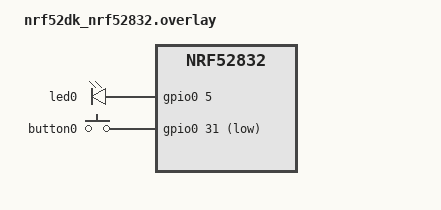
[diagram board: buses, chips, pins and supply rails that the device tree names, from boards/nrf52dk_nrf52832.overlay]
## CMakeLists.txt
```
# SPDX-License-Identifier: Apache-2.0

cmake_minimum_required(VERSION 3.20.0)
find_package(Zephyr REQUIRED HINTS $ENV{ZEPHYR_BASE})
project(blinky_1)

target_sources(app PRIVATE
    src/main.c
    src/uart_switch.c
    src/led.c
    src/gps.c
    src/modem.c
    src/ble.c
    src/state_machine.c
)
```

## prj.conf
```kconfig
CONFIG_GPIO=y

# nrfx UARTE0 owned directly (single UART, runtime pin-swap)
CONFIG_NRFX_UARTE0=y

# RTT for debug (UART0 hardware is used for GPS/modem)
CONFIG_USE_SEGGER_RTT=y
CONFIG_RTT_CONSOLE=y
CONFIG_UART_CONSOLE=n

# BLE + Nordic UART Service (NUS) for phone connection
CONFIG_BT=y
CONFIG_BT_PERIPHERAL=y
CONFIG_BT_NUS=y
CONFIG_BT_DEVICE_NAME="AKT-01"
CONFIG_BT_MAX_CONN=1

# FPU for double-precision GPS coordinates
CONFIG_FPU=y

# GPIOTE for interrupt-driven button
CONFIG_NRFX_GPIOTE=y

# Stack sizes
CONFIG_MAIN_STACK_SIZE=2048
CONFIG_SYSTEM_WORKQUEUE_STACK_SIZE=1024
```

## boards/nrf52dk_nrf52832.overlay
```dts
/ {
	chosen {
		zephyr,console = &rtt0;
		zephyr,shell-uart = &rtt0;
	};
};

&led0 {
	gpios = <&gpio0 5 GPIO_ACTIVE_HIGH>;
};

&button0 {
	gpios = <&gpio0 31 (GPIO_PULL_UP | GPIO_ACTIVE_LOW)>;
};

&uart0 {
	status = "disabled";
};
```

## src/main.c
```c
#include <zephyr/kernel.h>
#include <zephyr/sys/printk.h>
#include "uart_switch.h"
#include "led.h"
#include "gps.h"
#include "modem.h"
#include "ble.h"
#include "state_machine.h"

int main(void)
{
    printk("AKT-01 tracker boot\n");

    uart_switch_init();
    led_init();
    gps_init();
    ble_init();
    modem_init();
    state_machine_init();

    printk("Boot complete\n");

    state_machine_run();

    return 0;
}
```

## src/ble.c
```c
#include "ble.h"
#include <zephyr/kernel.h>
#include <zephyr/sys/util.h>
#include <zephyr/bluetooth/bluetooth.h>
#include <zephyr/bluetooth/conn.h>
#include <bluetooth/services/nus.h>
#include <string.h>
#include <zephyr/sys/printk.h>

static const struct bt_data ad[] = {
    BT_DATA_BYTES(BT_DATA_FLAGS, (BT_LE_AD_GENERAL | BT_LE_AD_NO_BREDR)),
    BT_DATA_BYTES(BT_DATA_UUID128_ALL, BT_UUID_NUS_VAL),
};

static const struct bt_data sd[] = {
    BT_DATA(BT_DATA_NAME_COMPLETE,
            CONFIG_BT_DEVICE_NAME,
            sizeof(CONFIG_BT_DEVICE_NAME) - 1),
};

static struct bt_conn *m_conn;

static void on_connected(struct bt_conn *conn, uint8_t err)
{
    if (err) {
        printk("BLE: connect failed (err %u)\n", err);
        return;
    }
    printk("BLE: phone connected\n");
    m_conn = bt_conn_ref(conn);
}

static void on_disconnected(struct bt_conn *conn, uint8_t reason)
{
    printk("BLE: phone disconnected (reason %u)\n", reason);
    if (m_conn) {
        bt_conn_unref(m_conn);
        m_conn = NULL;
    }

    bt_le_adv_start(BT_LE_ADV_CONN_FAST_1, ad, ARRAY_SIZE(ad), sd, ARRAY_SIZE(sd));
}

BT_CONN_CB_DEFINE(conn_callbacks) = {
    .connected    = on_connected,
    .disconnected = on_disconnected,
};

static void nus_received(struct bt_conn *conn, const uint8_t *data, uint16_t len)
{
    printk("BLE: rx %u bytes: %.*s\n", len, len, (const char *)data);
}

static struct bt_nus_cb nus_cb = {
    .received = nus_received,
};

void ble_init(void)
{
    int err = bt_enable(NULL);
    if (err) {
        printk("BLE: init failed (%d)\n", err);
        return;
    }

    err = bt_nus_init(&nus_cb);
    if (err) {
        printk("BLE: NUS init failed (%d)\n", err);
        return;
    }

    printk("BLE: initialized\n");

}

void ble_start(void)
{
    int err = bt_le_adv_start(BT_LE_ADV_CONN_FAST_1,
                               ad, ARRAY_SIZE(ad),
                               sd, ARRAY_SIZE(sd));
    if (err && err != -EALREADY) {
        printk("BLE: adv start failed (%d)\n", err);
    } else {
        printk("BLE: advertising as \"%s\"\n", CONFIG_BT_DEVICE_NAME);
    }
}

void ble_stop(void)
{
    if (m_conn) {
        bt_conn_disconnect(m_conn, BT_HCI_ERR_REMOTE_USER_TERM_CONN);
    }
    int err = bt_le_adv_stop();
    if (err) {
        printk("BLE: adv stop failed (%d)\n", err);
    }
    printk("BLE: stopped\n");
}

void ble_send_status(const char *text)
{
    if (m_conn) {
        bt_nus_send(m_conn, (const uint8_t *)text, strlen(text));
    }
}
```

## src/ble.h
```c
#ifndef BLE_H
#define BLE_H

void ble_init(void);

void ble_start(void);

void ble_stop(void);

void ble_send_status(const char *text);

#endif 
```

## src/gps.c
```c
#include "gps.h"
#include "uart_switch.h"
#include <zephyr/kernel.h>
#include <stdlib.h>
#include <string.h>
#include <zephyr/sys/printk.h>

#define PMTK_STANDBY  "$PMTK161,0*28\r\n"
#define PMTK_WAKE     "$PMTK010,001*2E\r\n"

#define GPS_LINE_MAX  96u

static gps_fix_t  m_fix;
static char       m_line[GPS_LINE_MAX];
static uint8_t    m_line_len;

static double nmea_coord_to_decimal(const char *field, char hem)
{
    if (field[0] == '\0') {
        return 0.0;
    }
    int degree_digits = (hem == 'N' || hem == 'S') ? 2 : 3;

    char deg_str[4] = {0};
    memcpy(deg_str, field, degree_digits);

    double degrees = atof(deg_str);
    double minutes  = atof(field + degree_digits);
    double decimal  = degrees + (minutes / 60.0);

    if (hem == 'S' || hem == 'W') {
        decimal = -decimal;
    }
    return decimal;
}

static int split_fields(char *line, char *fields[], int max_fields)
{
    int count = 0;
    char *tok = line;

    while (count < max_fields) {
        fields[count++] = tok;
        char *comma = strchr(tok, ',');
        if (!comma) {
            break;
        }
        *comma = '\0';
        tok    = comma + 1;
    }
    return count;
}

static bool parse_gga(char *sentence)
{
    char *fields[15];
    int n = split_fields(sentence, fields, 15);

    if (n < 8) {
        return false;
    }

    int quality = atoi(fields[6]);
    if (quality == 0) {
        m_fix.valid = false;
        return false;
    }

    m_fix.latitude   = nmea_coord_to_decimal(fields[2], fields[3][0]);
    m_fix.longitude  = nmea_coord_to_decimal(fields[4], fields[5][0]);
    m_fix.satellites = (uint8_t)atoi(fields[7]);
    m_fix.valid      = true;
    return true;
}

static bool process_line(char *line)
{
    if (line[0] != '$') {
        return false;
    }

    char *star = strchr(line, '*');
    if (star) {
        *star = '\0';
    }

    if (strncmp(line + 1, "GPGGA", 5) == 0 ||
        strncmp(line + 1, "GNGGA", 5) == 0) {
        return parse_gga(line);
    }
    return false;
}

bool gps_feed_byte(uint8_t byte)
{
    if (byte == '\r') {
        return false;
    }
    if (byte == '\n') {
        bool got_fix = false;
        if (m_line_len > 0) {
            m_line[m_line_len] = '\0';
            got_fix = process_line(m_line);
        }
        m_line_len = 0;
        return got_fix;
    }
    if (m_line_len < GPS_LINE_MAX - 1u) {
        m_line[m_line_len++] = byte;
    }
    return false;
}

gps_fix_t gps_get_fix(void)
{
    return m_fix;
}

void gps_init(void)
{
    memset(&m_fix, 0, sizeof(m_fix));
    m_line_len = 0;
}

void gps_enter_standby(void)
{
    uart_switch_to_gps();
    uart_write_str(PMTK_STANDBY);
    k_sleep(K_MSEC(200));
}

bool gps_acquire_fix(gps_fix_t *fix, int timeout_ms)
{
    uart_switch_to_gps();
    uart_flush_rx();

    uart_write_str(PMTK_WAKE);

    int64_t deadline = k_uptime_get() + timeout_ms;
    uint8_t byte;

    while (k_uptime_get() < deadline) {
        if (!uart_read_byte(&byte, K_MSEC(200))) {
            continue;
        }
        if (gps_feed_byte(byte) && m_fix.valid) {
            *fix = m_fix;
            printk("GPS fix: lat=%d.%06d lon=%d.%06d sats=%u\n",
                   (int)m_fix.latitude,
                   (int)((m_fix.latitude < 0 ? -m_fix.latitude : m_fix.latitude) * 1e6) % 1000000,
                   (int)m_fix.longitude,
                   (int)((m_fix.longitude < 0 ? -m_fix.longitude : m_fix.longitude) * 1e6) % 1000000,
                   m_fix.satellites);
            return true;
        }
    }

    printk("GPS: fix timeout\n");
    return false;
}
```

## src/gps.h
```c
#ifndef GPS_H
#define GPS_H

#include <stdbool.h>
#include <stdint.h>

typedef struct {
    double  latitude;
    double  longitude;
    uint8_t satellites;
    bool    valid;
} gps_fix_t;

void gps_init(void);

bool gps_acquire_fix(gps_fix_t *fix, int timeout_ms);

void gps_enter_standby(void);

bool gps_feed_byte(uint8_t byte);

gps_fix_t gps_get_fix(void);

#endif
```

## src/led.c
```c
#include "led.h"
#include <zephyr/kernel.h>
#include <zephyr/drivers/gpio.h>

#define LED_NODE DT_ALIAS(led0)
static const struct gpio_dt_spec m_led = GPIO_DT_SPEC_GET(LED_NODE, gpios);

void led_init(void)
{
    gpio_pin_configure_dt(&m_led, GPIO_OUTPUT_INACTIVE);
}

void led_tx_on(void)
{
    gpio_pin_set_dt(&m_led, 1);
}

void led_tx_off(void)
{
    gpio_pin_set_dt(&m_led, 0);
}

void led_blink_fail(void)
{
    for (int i = 0; i < 3; i++) {
        gpio_pin_set_dt(&m_led, 1);
        k_sleep(K_MSEC(80));
        gpio_pin_set_dt(&m_led, 0);
        k_sleep(K_MSEC(120));
    }
}
```

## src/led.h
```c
#ifndef LED_H
#define LED_H

void led_init(void);

void led_tx_on(void);
void led_tx_off(void);

void led_blink_fail(void);

#endif 
```

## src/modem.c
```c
#include "modem.h"
#include "uart_switch.h"
#include "led.h"
#include <zephyr/kernel.h>
#include <string.h>
#include <stdio.h>
#include <stdlib.h>
#include <zephyr/sys/printk.h>

#define AT_LINE_MAX   256u
#define AT_TIMEOUT_MS 10000

static char m_line[AT_LINE_MAX];

static int read_line(int timeout_ms)
{
    int64_t deadline = k_uptime_get() + timeout_ms;
    uint8_t byte;
    int     len = 0;

    while (k_uptime_get() < deadline) {
        if (!uart_read_byte(&byte, K_MSEC(100))) {
            continue;
        }
        if (byte == '\r') {
            continue;
        }
        if (byte == '\n') {
            m_line[len] = '\0';
            return len;
        }
        if (len < (int)(AT_LINE_MAX - 1)) {
            m_line[len++] = (char)byte;
        }
    }
    m_line[len] = '\0';
    return -1;
}

static bool at_send(const char *cmd, const char *expect, int timeout_ms)
{
    printk("AT >> %s\n", cmd);
    uart_write_str(cmd);
    uart_write_str("\r\n");

    int64_t deadline = k_uptime_get() + timeout_ms;
    while (k_uptime_get() < deadline) {
        int remaining = (int)(deadline - k_uptime_get());
        if (remaining <= 0) {
            break;
        }
        int n = read_line(remaining < 500 ? remaining : 500);
        if (n < 0) {
            break;
        }
        if (n == 0) {
            continue; 
        }
        printk("AT << %s\n", m_line);
        if (strstr(m_line, expect)) {
            return true;
        }
        if (strstr(m_line, "ERROR")) {
            return false;
        }
    }
    printk("AT timeout waiting for '%s'\n", expect);
    return false;
}

void modem_init(void)
{
    uart_switch_to_modem();
    uart_flush_rx();

    k_sleep(K_MSEC(2000));

    at_send("AT",          "OK",  AT_TIMEOUT_MS);
    at_send("ATE0",        "OK",  AT_TIMEOUT_MS);
    at_send("AT+CMEE=2",   "OK",  AT_TIMEOUT_MS);

    char cmd[128];
    snprintf(cmd, sizeof(cmd), "AT+CGDCONT=1,\"IP\",\"%s\"", MODEM_APN);
    at_send(cmd, "OK", AT_TIMEOUT_MS);

    printk("Modem init done\n");
}

void modem_sleep(void)
{
    uart_switch_to_modem();
    at_send("AT+CSCLK=1", "OK", AT_TIMEOUT_MS);
}

void modem_wake(void)
{
    uart_switch_to_modem();
    uart_write_str("AT\r\n");
    k_sleep(K_MSEC(300));
    at_send("AT+CSCLK=0", "OK", AT_TIMEOUT_MS);
}

bool modem_send_location(double lat, double lon)
{
    uart_switch_to_modem();
    uart_flush_rx();

    if (!at_send("AT+CREG?", "+CREG:", 15000)) {
        printk("Modem: not registered\n");
        return false;
    }
    if (!strstr(m_line, ",1") && !strstr(m_line, ",5")) {
        printk("Modem: registration status not OK: %s\n", m_line);
        return false;
    }

    at_send("AT+CGACT=1,1", "OK", 30000);

    int lat_sign = (lat < 0.0) ? -1 : 1;
    double lat_a = (lat < 0.0) ? -lat : lat;
    int lon_sign = (lon < 0.0) ? -1 : 1;
    double lon_a = (lon < 0.0) ? -lon : lon;

    int lat_deg  = (int)lat_a;
    int lat_frac = (int)((lat_a - lat_deg) * 1000000.0 + 0.5);
    int lon_deg  = (int)lon_a;
    int lon_frac = (int)((lon_a - lon_deg) * 1000000.0 + 0.5);

    char url[512];
    snprintf(url, sizeof(url),
             "AT+HTTPPARA=\"URL\",\"%s?lat=%s%d.%06d&lon=%s%d.%06d\"",
             TRACKER_ENDPOINT,
             (lat_sign < 0) ? "-" : "", lat_deg, lat_frac,
             (lon_sign < 0) ? "-" : "", lon_deg, lon_frac);

    if (!at_send("AT+HTTPINIT", "OK", 5000)) {
        return false;
    }
    if (!at_send("AT+HTTPPARA=\"CID\",1", "OK", 5000)) {
        at_send("AT+HTTPTERM", "OK", 5000);
        return false;
    }
    if (!at_send(url, "OK", 5000)) {
        at_send("AT+HTTPTERM", "OK", 5000);
        return false;
    }

    led_tx_on();

    bool ok = false;
    if (at_send("AT+HTTPACTION=0", "+HTTPACTION:", 30000)) {
        char *p = strstr(m_line, ",");
        if (p) {
            int status_code = atoi(p + 1);
            printk("HTTP status: %d\n", status_code);
            ok = (status_code == 200);
        }
    }

    led_tx_off();

    at_send("AT+HTTPTERM", "OK", 5000);

    return ok;
}
```

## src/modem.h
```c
#ifndef MODEM_H
#define MODEM_H

#include <stdbool.h>

#define TRACKER_ENDPOINT  "http://YOUR_APPS_SCRIPT_URL_HERE"

/*
 * APN for your SIM.  Beeline KZ example: "internet.beeline.kz"
 */
#define MODEM_APN  "internet"

void modem_init(void);

bool modem_send_location(double lat, double lon);

void modem_sleep(void);

void modem_wake(void);

#endif
```

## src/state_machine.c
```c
#include "state_machine.h"
#include "gps.h"
#include "modem.h"
#include "ble.h"
#include "led.h"
#include <zephyr/kernel.h>
#include <zephyr/drivers/gpio.h>
#include <zephyr/sys/printk.h>

/* ── State ───────────────────────────────────────────────────────────── */
typedef enum { STATE_SLEEP, STATE_AWAKE } device_state_t;
static volatile device_state_t m_state = STATE_SLEEP;

/* ── Button ──────────────────────────────────────────────────────────── */
#define BUTTON_NODE DT_ALIAS(sw0)
static const struct gpio_dt_spec m_btn = GPIO_DT_SPEC_GET(BUTTON_NODE, gpios);
static struct gpio_callback      m_btn_cb;

static K_SEM_DEFINE(m_btn_sem, 0, 1);

static void button_isr(const struct device *dev, struct gpio_callback *cb,
                        uint32_t pins)
{
    ARG_UNUSED(dev);
    ARG_UNUSED(cb);
    ARG_UNUSED(pins);
    k_sem_give(&m_btn_sem);
}

/* ── Cycle timer + semaphore ─────────────────────────────────────────── */
static K_SEM_DEFINE(m_cycle_sem, 0, 1);

static void cycle_timer_cb(struct k_timer *t)
{
    ARG_UNUSED(t);
    k_sem_give(&m_cycle_sem);
}

K_TIMER_DEFINE(m_cycle_timer, cycle_timer_cb, NULL);

/* ── Cycle thread ────────────────────────────────────────────────────── */
#define CYCLE_THREAD_STACK  4096
#define CYCLE_THREAD_PRIO   5

static void cycle_thread_fn(void *a, void *b, void *c)
{
    ARG_UNUSED(a); ARG_UNUSED(b); ARG_UNUSED(c);

    while (1) {
        k_sem_take(&m_cycle_sem, K_FOREVER);

        if (m_state != STATE_AWAKE) {
            continue;
        }

        printk("Cycle: starting fix→upload\n");

        /* ── GPS ─────────────────────────────────────────────────────── */
        gps_fix_t fix;
        bool got_fix = gps_acquire_fix(&fix, GPS_FIX_TIMEOUT_MS);

        if (!got_fix) {
            printk("Cycle: no GPS fix — skipping upload\n");
            led_blink_fail();
            continue;
        }

        /* ── Upload ──────────────────────────────────────────────────── */
        bool uploaded = modem_send_location(fix.latitude, fix.longitude);

        if (!uploaded) {
            printk("Cycle: upload failed\n");
            led_blink_fail();
        } else {
            printk("Cycle: upload OK\n");

            char buf[64];
            int lat_deg  = (int)(fix.latitude < 0 ? -fix.latitude : fix.latitude);
            int lat_frac = (int)((fix.latitude < 0 ? -fix.latitude : fix.latitude) * 1e6) % 1000000;
            int lon_deg  = (int)(fix.longitude < 0 ? -fix.longitude : fix.longitude);
            int lon_frac = (int)((fix.longitude < 0 ? -fix.longitude : fix.longitude) * 1e6) % 1000000;

            snprintf(buf, sizeof(buf), "%s%d.%06d,%s%d.%06d",
                     fix.latitude  < 0 ? "-" : "", lat_deg, lat_frac,
                     fix.longitude < 0 ? "-" : "", lon_deg, lon_frac);
            ble_send_status(buf);
        }
    }
}

K_THREAD_DEFINE(cycle_tid,
                CYCLE_THREAD_STACK,
                cycle_thread_fn,
                NULL, NULL, NULL,
                CYCLE_THREAD_PRIO, 0, 0);

/* ── State transitions ───────────────────────────────────────────────── */
static void enter_awake(void)
{
    printk("-> AWAKE\n");
    m_state = STATE_AWAKE;
    ble_start();
    k_sem_give(&m_cycle_sem);
    k_timer_start(&m_cycle_timer,
                  K_SECONDS(CYCLE_INTERVAL_S),
                  K_SECONDS(CYCLE_INTERVAL_S));
}

static void enter_sleep(void)
{
    printk("-> SLEEP\n");
    m_state = STATE_SLEEP;
    k_timer_stop(&m_cycle_timer);
    ble_stop();
    gps_enter_standby();
    modem_sleep();
}

/* ── Public API ──────────────────────────────────────────────────────── */

void state_machine_init(void)
{
    gpio_pin_configure_dt(&m_btn, GPIO_INPUT);
    gpio_pin_interrupt_configure_dt(&m_btn, GPIO_INT_EDGE_TO_ACTIVE);
    gpio_init_callback(&m_btn_cb, button_isr, BIT(m_btn.pin));
    gpio_add_callback(m_btn.port, &m_btn_cb);

    printk("State machine ready, starting in SLEEP\n");
}

void state_machine_run(void)
{
    while (1) {
        k_sem_take(&m_btn_sem, K_FOREVER);
        k_sleep(K_MSEC(50)); /* debounce */

        while (k_sem_take(&m_btn_sem, K_NO_WAIT) == 0) {
        }

        if (m_state == STATE_SLEEP) {
            enter_awake();
        } else {
            enter_sleep();
        }
    }
}
```

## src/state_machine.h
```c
#ifndef STATE_MACHINE_H
#define STATE_MACHINE_H

#define CYCLE_INTERVAL_S  300  

#define GPS_FIX_TIMEOUT_MS  90000 

void state_machine_init(void);

void state_machine_run(void);

#endif
```

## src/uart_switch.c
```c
#include "uart_switch.h"
#include <zephyr/kernel.h>
#include <zephyr/irq.h>
#include <string.h>
#include <nrfx_uarte.h>       
#include <haly/nrfy_uarte.h>

/* ── Pin assignments ─────────────────────────────────────────────────── */
#define GPS_PIN_TX   23u 
#define GPS_PIN_RX   22u  
#define GPS_BAUD     NRF_UARTE_BAUDRATE_9600

#define MDM_PIN_TX   13u   
#define MDM_PIN_RX   11u   
#define MDM_BAUD     NRF_UARTE_BAUDRATE_115200

/* ── RX ring buffer ──────────────────────────────────────────────────── */
#define RING_POW   8u                
#define RING_SZ    (1u << RING_POW)
#define RING_MASK  (RING_SZ - 1u)

static uint8_t         m_ring[RING_SZ];
static volatile uint32_t m_ring_head; 
static uint32_t        m_ring_tail;   

/* ── DMA ping-pong buffers ───────────────────────────────────────────── */
#define DMA_BUF_SZ  32u
static uint8_t m_buf_a[DMA_BUF_SZ];
static uint8_t m_buf_b[DMA_BUF_SZ];
static uint8_t *m_next_buf = m_buf_b;  

/* ── nrfx instance ───────────────────────────────────────────────────── */
static nrfx_uarte_t m_uarte = NRFX_UARTE_INSTANCE(0);
static bool         m_initialized;

/* ── ISR / event handler ─────────────────────────────────────────────── */
static void uarte_evt(nrfx_uarte_event_t const *ev, void *ctx)
{
    ARG_UNUSED(ctx);

    switch (ev->type) {
    case NRFX_UARTE_EVT_RX_BUF_REQUEST:
        nrfx_uarte_rx_buffer_set(&m_uarte, m_next_buf, DMA_BUF_SZ);
        break;

    case NRFX_UARTE_EVT_RX_DONE: {
        const uint8_t *p   = ev->data.rx.p_data;
        size_t         len = ev->data.rx.length;
        uint32_t       head = m_ring_head;

        for (size_t i = 0; i < len; i++) {
            if ((head - m_ring_tail) < RING_SZ) {
                m_ring[head & RING_MASK] = p[i];
                head++;
            }
        }
        m_ring_head = head;

        m_next_buf = (uint8_t *)p;
        break;
    }

    case NRFX_UARTE_EVT_TX_DONE:
        break;

    case NRFX_UARTE_EVT_ERROR:
        break;

    default:
        break;
    }
}

static void do_switch(uint32_t tx_pin, uint32_t rx_pin, nrf_uarte_baudrate_t baud)
{
    if (m_initialized) {
        nrfx_uarte_uninit(&m_uarte);
        nrfy_uarte_int_init(NRF_UARTE0, 0xFFFFFFFFu, 0, false);
        m_initialized = false;
    }

    nrfx_uarte_config_t cfg = NRFX_UARTE_DEFAULT_CONFIG(tx_pin, rx_pin);
    cfg.baudrate = baud;

    int err = nrfx_uarte_init(&m_uarte, &cfg, uarte_evt);
    if (err != 0) {
        return;
    }
    m_initialized = true;

    m_ring_head = 0;
    m_ring_tail = 0;
    m_next_buf  = m_buf_b;

    nrfx_uarte_rx_buffer_set(&m_uarte, m_buf_a, DMA_BUF_SZ);
    nrfx_uarte_rx_enable(&m_uarte, 0);
}

/* ── Public API ──────────────────────────────────────────────────────── */

void uart_switch_init(void)
{
    IRQ_CONNECT(DT_IRQN(DT_NODELABEL(uart0)),
                DT_IRQ(DT_NODELABEL(uart0), priority),
                nrfx_isr,
                nrfx_uarte_0_irq_handler,
                0);
    irq_enable(DT_IRQN(DT_NODELABEL(uart0)));

    do_switch(GPS_PIN_TX, GPS_PIN_RX, GPS_BAUD);
}

void uart_switch_to_gps(void)
{
    do_switch(GPS_PIN_TX, GPS_PIN_RX, GPS_BAUD);
}

void uart_switch_to_modem(void)
{
    do_switch(MDM_PIN_TX, MDM_PIN_RX, MDM_BAUD);
}

void uart_write(const uint8_t *data, size_t len)
{
    if (!m_initialized || len == 0) {
        return;
    }
    nrfx_uarte_tx(&m_uarte, data, len, 0);
}

void uart_write_str(const char *s)
{
    if (s) {
        uart_write((const uint8_t *)s, strlen(s));
    }
}

bool uart_read_byte(uint8_t *out, k_timeout_t timeout)
{
    int64_t deadline = k_uptime_get() + k_ticks_to_ms_floor64(timeout.ticks);

    while (m_ring_tail == m_ring_head) {
        if (k_uptime_get() >= deadline) {
            return false;
        }
        k_sleep(K_MSEC(1));
    }

    *out = m_ring[m_ring_tail & RING_MASK];
    m_ring_tail++;
    return true;
}

void uart_flush_rx(void)
{
    m_ring_tail = m_ring_head;
}
```

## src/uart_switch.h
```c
#ifndef UART_SWITCH_H
#define UART_SWITCH_H

#include <stdint.h>
#include <stddef.h>
#include <stdbool.h>
#include <zephyr/kernel.h>

void uart_switch_init(void);
void uart_switch_to_gps(void);
void uart_switch_to_modem(void);

void uart_write(const uint8_t *data, size_t len);

void uart_write_str(const char *s);

bool uart_read_byte(uint8_t *out, k_timeout_t timeout);

void uart_flush_rx(void);

#endif
```
